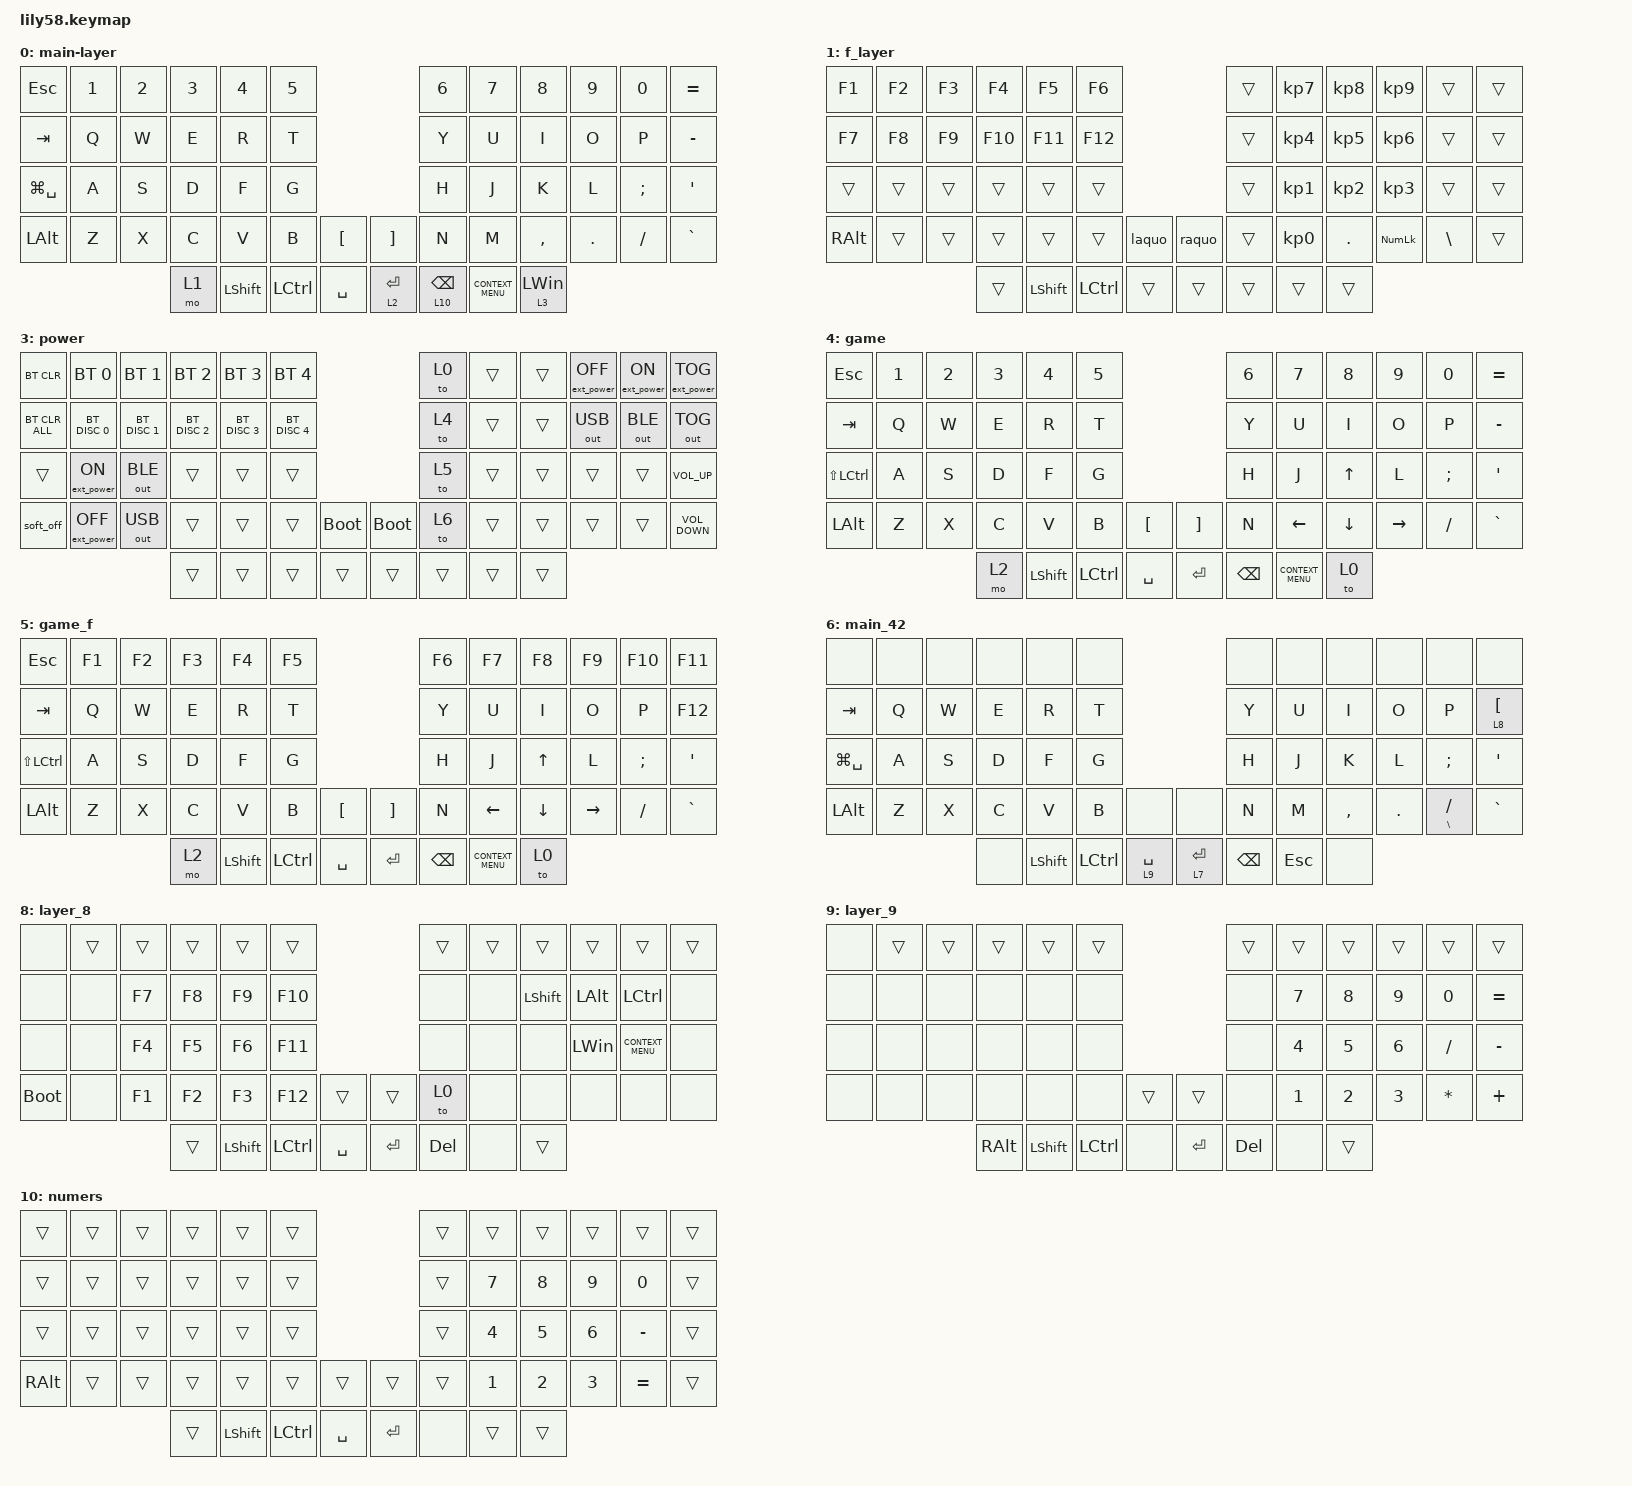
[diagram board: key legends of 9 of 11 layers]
/*
 * Copyright (c) 2020 The ZMK Contributors
 *
 * SPDX-License-Identifier: MIT
 */

#include <behaviors.dtsi>
#include <dt-bindings/zmk/bt.h>
#include <dt-bindings/zmk/ext_power.h>
#include <dt-bindings/zmk/keys.h>
#include <dt-bindings/zmk/outputs.h>

/ {
    combos { compatible = "zmk,combos"; };

    behaviors {
        ss_hs_modmorph: ss_hs_modmorph {
            compatible = "zmk,behavior-mod-morph";
            label = "SS_HS_MODMORPH";
            bindings = <&kp M>, <&kp RIGHT_BRACKET>;

            #binding-cells = <0>;
            mods = <(MOD_LSFT|MOD_RSFT)>;
        };

        kh_hs_tapdance: kh_hs_tapdance {
            compatible = "zmk,behavior-tap-dance";
            label = "KH_HS_TAPDANCE";
            #binding-cells = <0>;
            tapping-term-ms = <200>;
            bindings = <&kp LEFT_BRACKET>, <&kp RIGHT_BRACKET>;
        };

        hrm: hrm {
            compatible = "zmk,behavior-hold-tap";
            #binding-cells = <2>;
            flavor = "tap-preferred";
            tapping-term-ms = <200>;
            quick-tap-ms = <200>;
            require-prior-idle-ms = <125>;
            bindings = <&kp>, <&kp>;
        };
    };

    macros {
        laquo: laquo {
            compatible = "zmk,behavior-macro";
            label = "LAQUO";
            #binding-cells = <0>;
            bindings =
                <&macro_press>,
                <&kp LALT>,
                <&macro_tap>,
                <&kp KP_N0 &kp KP_N1 &kp KP_N7 &kp KP_N1>,
                <&macro_release>,
                <&kp LALT>;
        };

        raquo: raquo {
            compatible = "zmk,behavior-macro";
            label = "RAQUO";
            #binding-cells = <0>;
            bindings =
                <&macro_press>,
                <&kp LALT>,
                <&macro_tap>,
                <&kp KP_N0 &kp KP_N1 &kp KP_N8 &kp KP_N7>,
                <&macro_release>,
                <&kp LALT>;
        };
    };

    keymap {
        compatible = "zmk,keymap";

        main-layer {
            bindings = <
&kp ESCAPE     &kp N1  &kp N2  &kp N3  &kp N4          &kp N5                                            &kp N6            &kp N7              &kp N8          &kp N9   &kp N0     &kp EQUAL
&kp TAB        &kp Q   &kp W   &kp E   &kp R           &kp T                                             &kp Y             &kp U               &kp I           &kp O    &kp P      &kp MINUS
&kp LG(SPACE)  &kp A   &kp S   &kp D   &kp F           &kp G                                             &kp H             &kp J               &kp K           &kp L    &kp SEMI   &kp SQT
&kp LEFT_ALT   &kp Z   &kp X   &kp C   &kp V           &kp B      &kp LEFT_BRACKET    &kp RIGHT_BRACKET  &kp N             &kp M               &kp COMMA       &kp DOT  &kp SLASH  &kp GRAVE
                               &mo 1   &kp LEFT_SHIFT  &kp LCTRL  &kp SPACE           &lt 2 ENTER        &lt 10 BACKSPACE  &kp K_CONTEXT_MENU  &lt 3 LEFT_WIN
            >;
        };

        f_layer {
            bindings = <
&kp F1         &kp F2  &kp F3  &kp F4   &kp F5          &kp F6                       &trans  &kp KP_N7        &kp KP_NUMBER_8  &kp KP_NUMBER_9  &trans         &trans
&kp F7         &kp F8  &kp F9  &kp F10  &kp F11         &kp F12                      &trans  &kp KP_NUMBER_4  &kp KP_NUMBER_5  &kp KP_NUMBER_6  &trans         &trans
&trans         &trans  &trans  &trans   &trans          &trans                       &trans  &kp KP_NUMBER_1  &kp KP_NUMBER_2  &kp KP_NUMBER_3  &trans         &trans
&kp RIGHT_ALT  &trans  &trans  &trans   &trans          &trans     &laquo    &raquo  &trans  &kp KP_NUMBER_0  &kp PERIOD       &kp KP_NUMLOCK   &kp BACKSLASH  &trans
                               &trans   &kp LEFT_SHIFT  &kp LCTRL  &trans    &trans  &trans  &trans           &trans
            >;
        };

        arrows {
            bindings = <
&kp PAUSE_BREAK  &trans  &trans  &trans        &trans          &trans                                                                &trans      &kp PG_UP       &kp INS         &kp PAGE_DOWN    &trans     &trans
&trans           &trans  &trans  &trans        &trans          &trans                                                                &trans      &kp HOME        &kp UP_ARROW    &kp END          &trans     &trans
&trans           &trans  &trans  &trans        &trans          &trans                                                                &trans      &kp LEFT_ARROW  &kp DOWN_ARROW  &kp RIGHT_ARROW  &trans     &kp PRINTSCREEN
&kp RIGHT_ALT    &trans  &trans  &trans        &trans          &trans  &mt LEFT_BRACE LEFT_BRACKET    &mt RIGHT_BRACE RIGHT_BRACKET  &trans      &trans          &trans          &trans           &kp SLASH  &trans
                                 &kp LEFT_WIN  &kp LEFT_SHIFT  &none   &trans                         &trans                         &kp DELETE  &trans
            >;
        };

        power {
            bindings = <
&bt BT_CLR      &bt BT_SEL 0       &bt BT_SEL 1   &bt BT_SEL 2   &bt BT_SEL 3   &bt BT_SEL 4                               &to 0   &trans  &trans  &ext_power EP_OFF  &ext_power EP_ON  &ext_power EP_TOG
&bt BT_CLR_ALL  &bt BT_DISC 0      &bt BT_DISC 1  &bt BT_DISC 2  &bt BT_DISC 3  &bt BT_DISC 4                              &to 4   &trans  &trans  &out OUT_USB       &out OUT_BLE      &out OUT_TOG
&trans          &ext_power EP_ON   &out OUT_BLE   &trans         &trans         &trans                                     &to 5   &trans  &trans  &trans             &trans            &kp C_VOLUME_UP
&soft_off       &ext_power EP_OFF  &out OUT_USB   &trans         &trans         &trans         &bootloader    &bootloader  &to 6   &trans  &trans  &trans             &trans            &kp C_VOLUME_DOWN
                                                  &trans         &trans         &trans         &trans         &trans       &trans  &trans  &trans
            >;
        };

        game {
            bindings = <
&kp ESCAPE     &kp N1  &kp N2  &kp N3  &kp N4          &kp N5                                            &kp N6         &kp N7              &kp N8          &kp N9           &kp N0     &kp EQUAL
&kp TAB        &kp Q   &kp W   &kp E   &kp R           &kp T                                             &kp Y          &kp U               &kp I           &kp O            &kp P      &kp MINUS
&kp LS(LCTRL)  &kp A   &kp S   &kp D   &kp F           &kp G                                             &kp H          &kp J               &kp UP_ARROW    &kp L            &kp SEMI   &kp SQT
&kp LEFT_ALT   &kp Z   &kp X   &kp C   &kp V           &kp B      &kp LEFT_BRACKET    &kp RIGHT_BRACKET  &kp N          &kp LEFT_ARROW      &kp DOWN_ARROW  &kp RIGHT_ARROW  &kp SLASH  &kp GRAVE
                               &mo 2   &kp LEFT_SHIFT  &kp LCTRL  &kp SPACE           &kp ENTER          &kp BACKSPACE  &kp K_CONTEXT_MENU  &to 0
            >;
        };

        game_f {
            bindings = <
&kp ESCAPE     &kp F1  &kp F2  &kp F3  &kp F4          &kp F5                                            &kp F6         &kp F7              &kp F8          &kp F9           &kp F10    &kp F11
&kp TAB        &kp Q   &kp W   &kp E   &kp R           &kp T                                             &kp Y          &kp U               &kp I           &kp O            &kp P      &kp F12
&kp LS(LCTRL)  &kp A   &kp S   &kp D   &kp F           &kp G                                             &kp H          &kp J               &kp UP_ARROW    &kp L            &kp SEMI   &kp SQT
&kp LEFT_ALT   &kp Z   &kp X   &kp C   &kp V           &kp B      &kp LEFT_BRACKET    &kp RIGHT_BRACKET  &kp N          &kp LEFT_ARROW      &kp DOWN_ARROW  &kp RIGHT_ARROW  &kp SLASH  &kp GRAVE
                               &mo 2   &kp LEFT_SHIFT  &kp LCTRL  &kp SPACE           &kp ENTER          &kp BACKSPACE  &kp K_CONTEXT_MENU  &to 0
            >;
        };

        main_42 {
            bindings = <
&none          &none  &none  &none  &none           &none                                  &none          &none       &none      &none    &none                &none
&kp TAB        &kp Q  &kp W  &kp E  &kp R           &kp T                                  &kp Y          &kp U       &kp I      &kp O    &kp P                &lt 8 LEFT_BRACKET
&kp LG(SPACE)  &kp A  &kp S  &kp D  &kp F           &kp G                                  &kp H          &kp J       &kp K      &kp L    &kp SEMI             &kp SQT
&kp LEFT_ALT   &kp Z  &kp X  &kp C  &kp V           &kp B      &none          &none        &kp N          &kp M       &kp COMMA  &kp DOT  &mt BACKSLASH SLASH  &kp GRAVE
                             &none  &kp LEFT_SHIFT  &kp LCTRL  &lt 9 SPACE    &lt 7 ENTER  &kp BACKSPACE  &kp ESCAPE  &none
            >;
        };

        arrow_42 {
            bindings = <
&trans  &trans  &trans  &trans          &trans             &trans                                     &trans                 &trans          &trans          &trans           &trans  &trans
&none   &trans  &trans  &kp MINUS       &kp SINGLE_QUOTE   &kp LEFT_PARENTHESIS                       &kp RIGHT_PARENTHESIS  &kp PG_UP       &kp INS         &kp PAGE_DOWN    &none   &kp PRINTSCREEN
&trans  &trans  &trans  &kp EQUAL       &kp DOUBLE_QUOTES  &kp LEFT_BRACKET                           &kp RIGHT_BRACKET      &kp HOME        &kp UP_ARROW    &kp END          &none   &kp C_VOLUME_UP
&trans  &trans  &trans  &kp UNDERSCORE  &kp QMARK          &kp LESS_THAN         &trans       &trans  &kp GREATER_THAN       &kp LEFT_ARROW  &kp DOWN_ARROW  &kp RIGHT_ARROW  &none   &kp C_VOLUME_DOWN
                        &trans          &kp LEFT_SHIFT     &kp LCTRL             &kp SPACE    &none   &kp DELETE             &none
            >;
        };

        layer_8 {
            bindings = <
&none        &trans  &trans  &trans  &trans          &trans                             &trans      &trans  &trans          &trans        &trans              &trans
&none        &none   &kp F7  &kp F8  &kp F9          &kp F10                            &none       &none   &kp LEFT_SHIFT  &kp LEFT_ALT  &kp LCTRL           &none
&none        &none   &kp F4  &kp F5  &kp F6          &kp F11                            &none       &none   &none           &kp LEFT_WIN  &kp K_CONTEXT_MENU  &none
&bootloader  &none   &kp F1  &kp F2  &kp F3          &kp F12    &trans       &trans     &to 0       &none   &none           &none         &none               &none
                             &trans  &kp LEFT_SHIFT  &kp LCTRL  &kp SPACE    &kp ENTER  &kp DELETE  &none   &trans
            >;
        };

        layer_9 {
            bindings = <
&none  &trans  &trans  &trans         &trans          &trans                          &trans      &trans        &trans        &trans        &trans        &trans
&none  &none   &none   &none          &none           &none                           &none       &kp NUMBER_7  &kp NUMBER_8  &kp N9        &kp NUMBER_0  &kp EQUAL
&none  &none   &none   &none          &none           &none                           &none       &kp NUMBER_4  &kp NUMBER_5  &kp NUMBER_6  &kp SLASH     &kp MINUS
&none  &none   &none   &none          &none           &none      &trans    &trans     &none       &kp NUMBER_1  &kp NUMBER_2  &kp NUMBER_3  &kp STAR      &kp PLUS
                       &kp RIGHT_ALT  &kp LEFT_SHIFT  &kp LCTRL  &none     &kp ENTER  &kp DELETE  &none         &trans
            >;
        };

        numers {
            bindings = <
&trans         &trans  &trans  &trans  &trans          &trans                             &trans  &trans        &trans        &trans        &trans        &trans
&trans         &trans  &trans  &trans  &trans          &trans                             &trans  &kp NUMBER_7  &kp NUMBER_8  &kp N9        &kp NUMBER_0  &trans
&trans         &trans  &trans  &trans  &trans          &trans                             &trans  &kp NUMBER_4  &kp NUMBER_5  &kp NUMBER_6  &kp MINUS     &trans
&kp RIGHT_ALT  &trans  &trans  &trans  &trans          &trans     &trans       &trans     &trans  &kp NUMBER_1  &kp NUMBER_2  &kp NUMBER_3  &kp EQUAL     &trans
                               &trans  &kp LEFT_SHIFT  &kp LCTRL  &kp SPACE    &kp ENTER  &none   &trans        &trans
            >;
        };
    };
};
